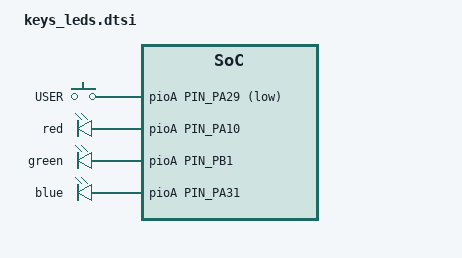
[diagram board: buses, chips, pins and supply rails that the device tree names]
/* microElk */
/ {
    gpio_keys {
        compatible      = "gpio-keys";
        pinctrl-names   = "default";
        pinctrl-0       = <&pinctrl_key_gpio_default>;
        pb4 {
            label       = "USER";
            gpios       = <&pioA PIN_PA29 GPIO_ACTIVE_LOW>;
            linux,code  = <0x104>;
            wakeup-source;
        };
    }; /* gpio_keys */
    leds {
        compatible      = "gpio-leds";
        pinctrl-names   = "default";
        pinctrl-0       = <&pinctrl_led_gpio_default>;
            red {
                label   = "red";
                gpios   = <&pioA PIN_PA10 GPIO_ACTIVE_HIGH>;
            }; /* red */
            green {
                label   = "green";
                gpios   = <&pioA PIN_PB1 GPIO_ACTIVE_HIGH>;
            }; /* green */
            blue {
                label   = "blue";
                gpios   = <&pioA PIN_PA31 GPIO_ACTIVE_HIGH>;
                linux,default-trigger = "heartbeat";
            }; /* blue */
    }; /* leds */
    ahb {
        apb { /* Advanced peripheral bus */
            /**************/
            /*** PINCTL ***/
            /**************/
            pinctrl@fc038000 {
                /************/
                /*** GPIO ***/
                /************/
                pinctrl_key_gpio_default: key_gpio_default {
                    pinmux =        <PIN_PA29__GPIO>;
                    bias-pull-up;
                }; /* key */
                pinctrl_led_gpio_default: led_gpio_default {
                    pinmux =        <PIN_PA10__GPIO>,
                                    <PIN_PB1__GPIO>,
                                    <PIN_PA31__GPIO>;
                    bias-pull-up;
                }; /* led */
            }; /* pinctrl@fc038000*/
        }; /* apb */
    }; /* ahb */
}; /* / */
